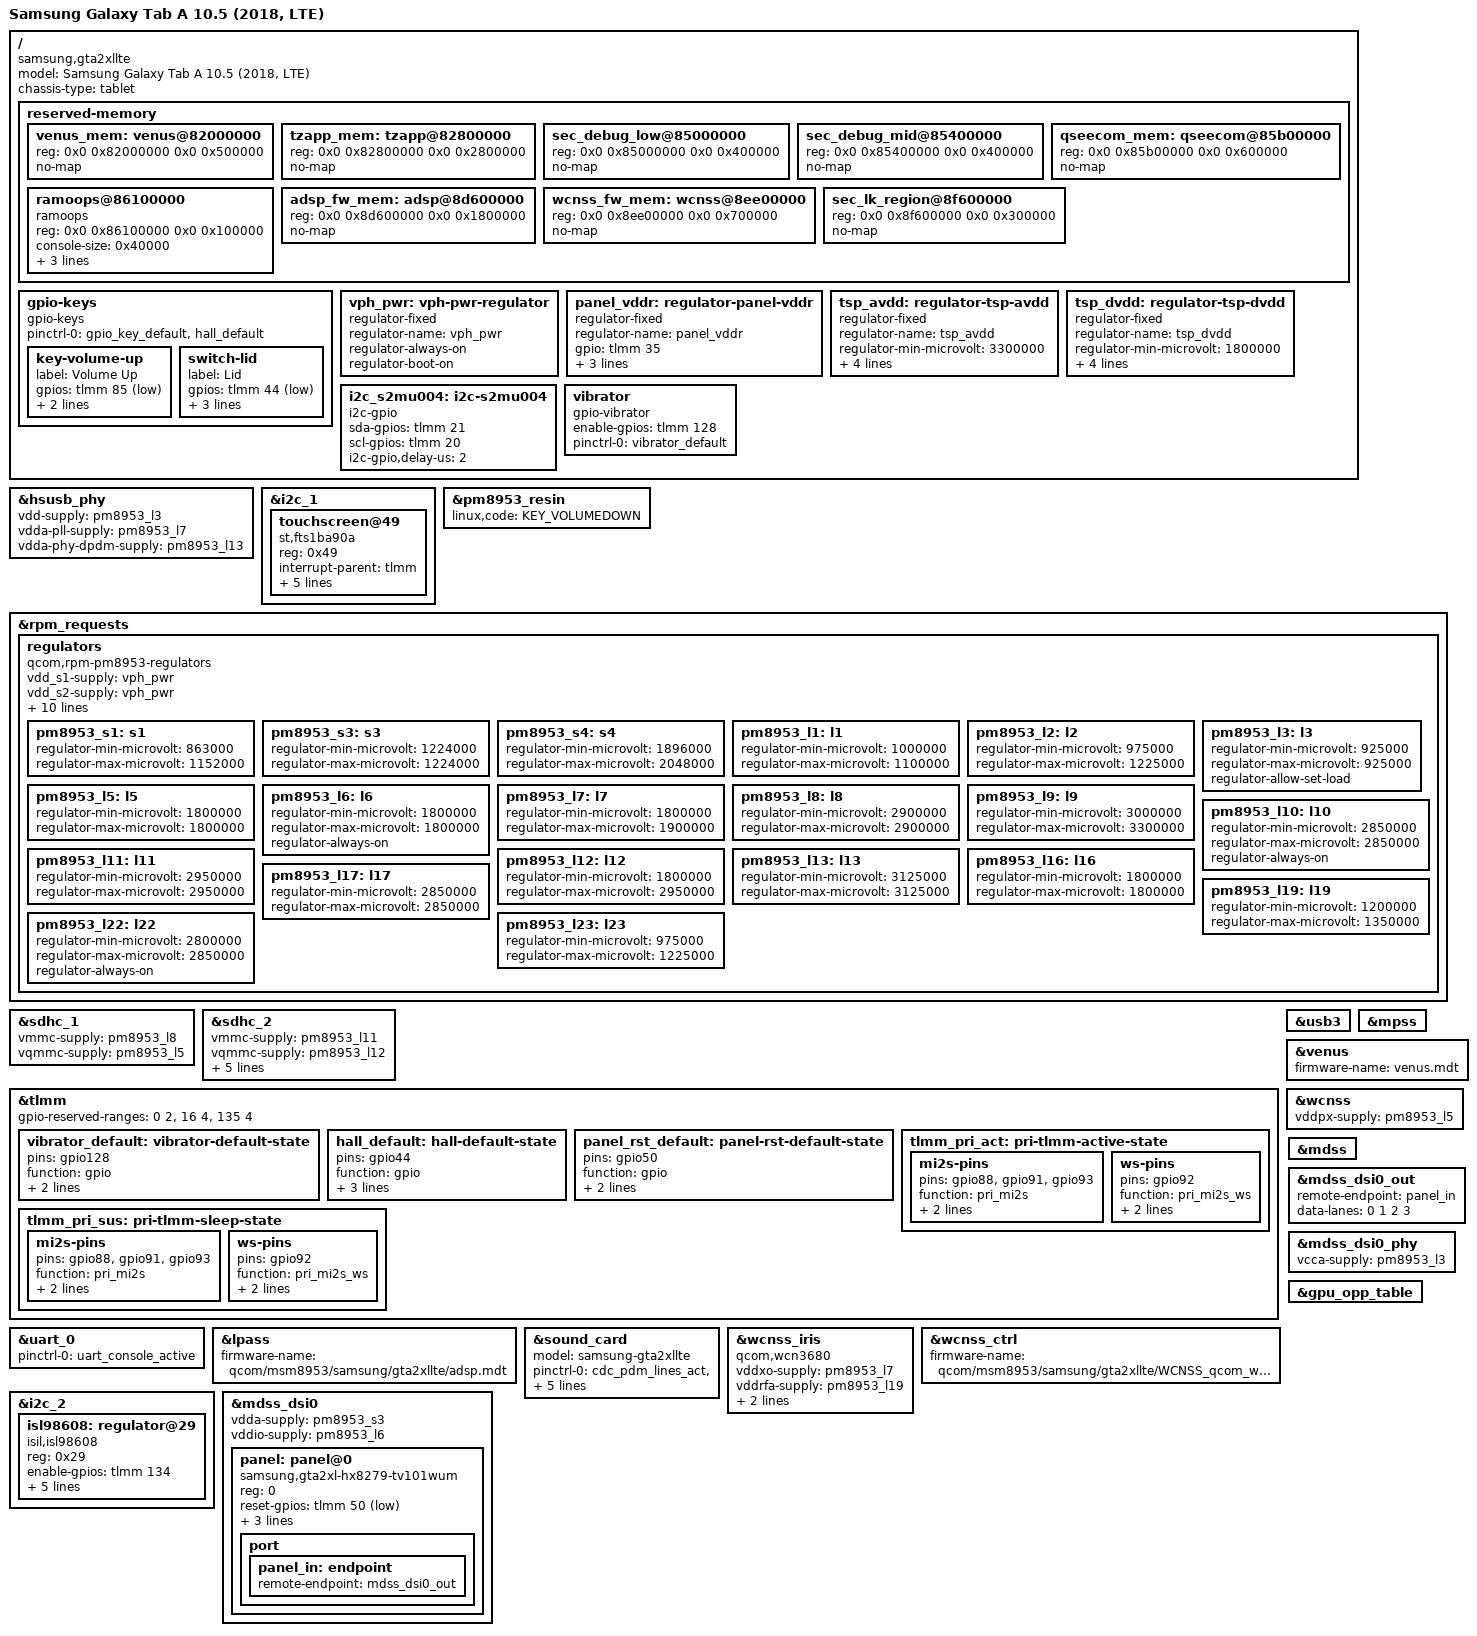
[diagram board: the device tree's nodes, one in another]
// SPDX-License-Identifier: GPL-2.0-only
/*
 * Samsung Galaxy Tab A 10.5 (2018, LTE) — "gta2xllte"
 * SoC: Qualcomm SDM450 / MSM8953 family
 *
 * testrung2 — riktig DSI-panel istället för simpledrm.
 *
 * SYFTE: msm-drivrutinen begär interconnect-bandbredd, det gör inte
 * simple-framebuffer. Därför dör bilden när venus probear klart och
 * interconnect kör sync_state(). Med &mdss aktiv ska både panelen och
 * venus fungera samtidigt.
 *
 * Ändringar mot testrung1:
 *   1. chosen/framebuffer BORTTAGEN — simpledrm och msm kan inte äga
 *      samma buffer.
 *   2. &mdss, &mdss_dsi0, &mdss_dsi0_phy = okay
 *   3. panel@0 med compatible "samsung,gta2xl-hx8279-tv101wum"
 *   4. &mdss_dsi0_out kopplad till panelen, 4 lanes
 *
 * KRÄVER att dessa drivrutiner är inbyggda i kärnan:
 *   panel-samsung-gta2xl-hx8279-tv101wum.c  (drivers/gpu/drm/panel/)
 *   isl98608-regulator.c                    (drivers/regulator/)
 * Saknas panel-drivern blir det INGEN bild alls. RAM-boota detta.
 *
 * OSÄKERT:
 *   - reset-gpio:ns aktiva nivå. Samsung anger den i panel-dtsi:n, inte i
 *     board-filen. GPIO_ACTIVE_LOW är det vanliga och vad drivern antar
 *     (devm_gpiod_get(..., GPIOD_OUT_HIGH) + set_value(1)->(0) i reset).
 *   - vdda/vddio/vcca-rails är tagna från msm8953-flipkart-rimob.dts, inte
 *     verifierade mot gta2xllte.
 *
 * Ingen backlight-property: panel-drivern registrerar egen DCS-backlight
 * (mipi_dsi_dcs_set_display_brightness_large), och Samsung anger
 * bl_ctrl_dcs. Det finns ingen pmi8950/wled på den här plattan.
 *
 * Inget behövs för zap: msm8953.dtsi har redan
 * firmware-name = "a506_zap.mdt" utan katalog, vilket matchar /lib/firmware-roten.
 * Inget behövs för tzapp: ingen nod refererar tzapp_mem, det är bara en
 * minnesreservering.
 */

/dts-v1/;

#include "sdm450.dtsi"
#include "pm8953.dtsi"

/delete-node/ &wcnss_fw_mem;

/delete-node/ &venus_mem;

/ {
	model = "Samsung Galaxy Tab A 10.5 (2018, LTE)";
	compatible = "samsung,gta2xllte", "qcom,sdm450";
	chassis-type = "tablet";

	reserved-memory {
		venus_mem: venus@82000000 {
			reg = <0x0 0x82000000 0x0 0x500000>;
			no-map;
		};

		tzapp_mem: tzapp@82800000 {
			reg = <0x0 0x82800000 0x0 0x2800000>;
			no-map;
		};

		sec_debug_low@85000000 {
			reg = <0x0 0x85000000 0x0 0x400000>;
			no-map;
		};

		sec_debug_mid@85400000 {
			reg = <0x0 0x85400000 0x0 0x400000>;
			no-map;
		};

		qseecom_mem: qseecom@85b00000 {
			reg = <0x0 0x85b00000 0x0 0x600000>;
			no-map;
		};

		ramoops@86100000 {
			compatible = "ramoops";
			reg = <0x0 0x86100000 0x0 0x100000>;

			console-size = <0x40000>;
			record-size = <0x3f800>;
			pmsg-size = <0x800>;
			ecc-size = <0>;
		};

		adsp_fw_mem: adsp@8d600000 {
			reg = <0x0 0x8d600000 0x0 0x1800000>;
			no-map;
		};

		wcnss_fw_mem: wcnss@8ee00000 {
			reg = <0x0 0x8ee00000 0x0 0x700000>;
			no-map;
		};

		sec_lk_region@8f600000 {
			reg = <0x0 0x8f600000 0x0 0x300000>;
			no-map;
		};
	};

	/*
	 * chosen/framebuffer (simpledrm) borttagen — msm-drivrutinen tar över
	 * displayen. Behöver du falla tillbaka: kopiera blocket från testrung1
	 * och sätt &mdss/&mdss_dsi0/&mdss_dsi0_phy till "disabled" igen.
	 *
	 * cont-splash-regionen ligger kvar reserverad (0x90001000, 20476 KiB)
	 * så lk2nd:s bild inte skrivs över innan msm är uppe.
	 */

	gpio-keys {
		compatible = "gpio-keys";

		pinctrl-names = "default";
		pinctrl-0 = <&gpio_key_default &hall_default>;

		key-volume-up {
			label = "Volume Up";
			gpios = <&tlmm 85 GPIO_ACTIVE_LOW>;
			linux,code = <KEY_VOLUMEUP>;
			wakeup-source;
		};

		/*
		 * Hall-sensor för magnetiskt fodral (book cover).
		 * Samsung: sdm450-sec-gta2xllte_eur_open-r05.dts rad 91,
		 *   hall { compatible = "hall";
		 *          hall,gpio_flip_cover = <&tlmm 44 0x1>; }
		 * 0x1 = aktiv låg. Rapporteras som SW_LID så logind/Plasma
		 * kan blanka skärmen när fodralet stängs.
		 */
		switch-lid {
			label = "Lid";
			gpios = <&tlmm 44 GPIO_ACTIVE_LOW>;
			linux,input-type = <EV_SW>;
			linux,code = <SW_LID>;
			wakeup-source;
		};

		/* Volume Down and Power are handled by the PMIC (see &pm8953_resin
		 * and the pm8953 pon below) */
	};

	vph_pwr: vph-pwr-regulator {
		compatible = "regulator-fixed";
		regulator-name = "vph_pwr";
		regulator-always-on;
		regulator-boot-on;
	};

	/*
	 * Panel VDDR (1.5V) extra rail — downstream samsung,panel-extra-power-gpio1
	 * on tlmm 35. The generated HX8279 driver doesn't request it, so assert it
	 * always-on so the panel has power before/through init.
	 */
	panel_vddr: regulator-panel-vddr {
		compatible = "regulator-fixed";
		regulator-name = "panel_vddr";
		gpio = <&tlmm 35 GPIO_ACTIVE_HIGH>;
		enable-active-high;
		regulator-always-on;
		regulator-boot-on;
	};

	/*
	 * Touchscreen power — downstream uses gpio-gated fixed regulators
	 * (NOT pm8953 rails): tsp_avdd 3.3V on tlmm 139, tsp_dvdd 1.8V on tlmm 140.
	 */
	tsp_avdd: regulator-tsp-avdd {
		compatible = "regulator-fixed";
		regulator-name = "tsp_avdd";
		regulator-min-microvolt = <3300000>;
		regulator-max-microvolt = <3300000>;
		gpio = <&tlmm 139 GPIO_ACTIVE_HIGH>;
		enable-active-high;
		regulator-boot-on;
	};

	tsp_dvdd: regulator-tsp-dvdd {
		compatible = "regulator-fixed";
		regulator-name = "tsp_dvdd";
		regulator-min-microvolt = <1800000>;
		regulator-max-microvolt = <1800000>;
		gpio = <&tlmm 140 GPIO_ACTIVE_HIGH>;
		enable-active-high;
		regulator-boot-on;
	};

	i2c_s2mu004: i2c-s2mu004 {
		compatible = "i2c-gpio";
		sda-gpios = <&tlmm 21 (GPIO_ACTIVE_HIGH | GPIO_OPEN_DRAIN)>;
		scl-gpios = <&tlmm 20 (GPIO_ACTIVE_HIGH | GPIO_OPEN_DRAIN)>;
		i2c-gpio,delay-us = <2>;	/* ~100 kHz */
		#address-cells = <1>;
		#size-cells = <0>;
	};
};

&hsusb_phy {
	vdd-supply = <&pm8953_l3>;
	vdda-pll-supply = <&pm8953_l7>;
	vdda-phy-dpdm-supply = <&pm8953_l13>;

	status = "okay";
};

&i2c_1 {
	status = "okay";

	touchscreen@49 {
		compatible = "st,fts1ba90a";
		reg = <0x49>;

		interrupt-parent = <&tlmm>;
		interrupts = <59 IRQ_TYPE_LEVEL_LOW>;

		vdd-supply = <&tsp_dvdd>;	/* 1.8V digital (tlmm 140) */
		avdd-supply = <&tsp_avdd>;	/* 3.3V analog (tlmm 139) */

		touchscreen-size-x = <1200>;
		touchscreen-size-y = <1920>;
	};
};

&pm8953_resin {
	linux,code = <KEY_VOLUMEDOWN>;
	status = "okay";
};

&rpm_requests {
	regulators {
		compatible = "qcom,rpm-pm8953-regulators";

		vdd_s1-supply = <&vph_pwr>;
		vdd_s2-supply = <&vph_pwr>;
		vdd_s3-supply = <&vph_pwr>;
		vdd_s4-supply = <&vph_pwr>;
		vdd_s5-supply = <&vph_pwr>;
		vdd_s6-supply = <&vph_pwr>;
		vdd_s7-supply = <&vph_pwr>;
		vdd_l1-supply = <&pm8953_s3>;
		vdd_l2_l3-supply = <&pm8953_s3>;
		vdd_l4_l5_l6_l7_l16_l19-supply = <&pm8953_s4>;
		vdd_l8_l11_l12_l13_l14_l15-supply = <&vph_pwr>;
		vdd_l9_l10_l17_l18_l22-supply = <&vph_pwr>;

		pm8953_s1: s1 {
			regulator-min-microvolt = <863000>;
			regulator-max-microvolt = <1152000>;
		};

		pm8953_s3: s3 {
			regulator-min-microvolt = <1224000>;
			regulator-max-microvolt = <1224000>;
		};

		pm8953_s4: s4 {
			regulator-min-microvolt = <1896000>;
			regulator-max-microvolt = <2048000>;
		};

		pm8953_l1: l1 {
			regulator-min-microvolt = <1000000>;
			regulator-max-microvolt = <1100000>;
		};

		pm8953_l2: l2 {
			regulator-min-microvolt = <975000>;
			regulator-max-microvolt = <1225000>;
		};

		pm8953_l3: l3 {
			regulator-min-microvolt = <925000>;
			regulator-max-microvolt = <925000>;
			regulator-allow-set-load;
		};

		pm8953_l5: l5 {
			regulator-min-microvolt = <1800000>;
			regulator-max-microvolt = <1800000>;
		};

		pm8953_l6: l6 {
			regulator-min-microvolt = <1800000>;
			regulator-max-microvolt = <1800000>;
			regulator-always-on;
		};

		pm8953_l7: l7 {
			regulator-min-microvolt = <1800000>;
			regulator-max-microvolt = <1900000>;
		};

		pm8953_l8: l8 {
			regulator-min-microvolt = <2900000>;
			regulator-max-microvolt = <2900000>;
		};

		pm8953_l9: l9 {
			regulator-min-microvolt = <3000000>;
			regulator-max-microvolt = <3300000>;
		};

		pm8953_l10: l10 {
			regulator-min-microvolt = <2850000>;
			regulator-max-microvolt = <2850000>;
			regulator-always-on;
		};

		pm8953_l11: l11 {
			regulator-min-microvolt = <2950000>;
			regulator-max-microvolt = <2950000>;
		};

		pm8953_l12: l12 {
			regulator-min-microvolt = <1800000>;
			regulator-max-microvolt = <2950000>;
		};

		pm8953_l13: l13 {
			regulator-min-microvolt = <3125000>;
			regulator-max-microvolt = <3125000>;
		};

		pm8953_l16: l16 {
			regulator-min-microvolt = <1800000>;
			regulator-max-microvolt = <1800000>;
		};

		pm8953_l17: l17 {
			regulator-min-microvolt = <2850000>;
			regulator-max-microvolt = <2850000>;
		};

		pm8953_l19: l19 {
			regulator-min-microvolt = <1200000>;
			regulator-max-microvolt = <1350000>;
		};

		pm8953_l22: l22 {
			regulator-min-microvolt = <2800000>;
			regulator-max-microvolt = <2850000>;
			regulator-always-on;
		};

		pm8953_l23: l23 {
			regulator-min-microvolt = <975000>;
			regulator-max-microvolt = <1225000>;
		};
	};
};

&sdhc_1 {
	vmmc-supply = <&pm8953_l8>;
	vqmmc-supply = <&pm8953_l5>;

	status = "okay";
};

&sdhc_2 {
	vmmc-supply = <&pm8953_l11>;
	vqmmc-supply = <&pm8953_l12>;

	cd-gpios = <&tlmm 133 GPIO_ACTIVE_LOW>;

	pinctrl-names = "default", "sleep";
	pinctrl-0 = <&sdc2_clk_on &sdc2_cmd_on &sdc2_data_on &sdc2_cd_on>;
	pinctrl-1 = <&sdc2_clk_off &sdc2_cmd_off &sdc2_data_off &sdc2_cd_off>;

	status = "okay";
};

&tlmm {
	gpio-reserved-ranges = <0 2>, <16 4>, <135 4>;
};

&uart_0 {
	pinctrl-names = "default";
	pinctrl-0 = <&uart_console_active>;

	status = "okay";
};

&usb3 {
	status = "okay";
};

&mpss {
	status = "okay";
};

&lpass {
	firmware-name = "qcom/msm8953/samsung/gta2xllte/adsp.mdt";
	status = "okay";
};

/*
 * Venus. Drivern probear redan och modulkedjan är laddad — det enda som
 * felade var firmwaren:
 *   "Direct firmware load for venus.mdt failed with error -2"
 * Ligger venus.mdt i /lib/firmware-roten behövs ingen firmware-name alls;
 * den här raden gör sökvägen explicit. Peka om den om du flyttar filen.
 */
&venus {
	firmware-name = "venus.mdt";
	status = "okay";
};

  &sound_card {
        model = "samsung-gta2xllte";

        pinctrl-names = "default", "sleep";
        pinctrl-0 = <&cdc_pdm_lines_act
                &cdc_pdm_lines_2_act
                &cdc_pdm_comp_lines_act
                &tlmm_pri_act>;
        pinctrl-1 = <&cdc_pdm_lines_sus
                &cdc_pdm_lines_2_sus
                &cdc_pdm_comp_lines_sus
                &tlmm_pri_sus>;

        status = "okay";
  };

&wcnss {
	vddpx-supply = <&pm8953_l5>;
	
	status = "okay";
};

&wcnss_iris {
	compatible = "qcom,wcn3680";

	vddxo-supply = <&pm8953_l7>;
	vddrfa-supply = <&pm8953_l19>;
	vddpa-supply = <&pm8953_l9>;
	vdddig-supply = <&pm8953_l5>;
};

&wcnss_ctrl {
	firmware-name = "qcom/msm8953/samsung/gta2xllte/WCNSS_qcom_wlan_nv.bin";
};

&i2c_2 {
	status = "okay";

	isl98608: regulator@29 {
		compatible = "isil,isl98608";
		reg = <0x29>;
		enable-gpios = <&tlmm 134 GPIO_ACTIVE_HIGH>;
		regulator-name = "panel_vsp_vsn";
		regulator-min-microvolt = <5800000>;
		regulator-max-microvolt = <5800000>;
		regulator-always-on;
		regulator-boot-on;
	};
};

&mdss {
	status = "okay";
};

&mdss_dsi0 {
	vdda-supply = <&pm8953_s3>;	/* 1.224 V — ej verifierad mot gta2 */
	vddio-supply = <&pm8953_l6>;	/* 1.8 V, always-on */

	status = "okay";

	panel: panel@0 {
		compatible = "samsung,gta2xl-hx8279-tv101wum";
		reg = <0>;

		/*
		 * LCD_RST. Samsung display-r00.dtsi listar gpio50 + gpio35 som
		 * "LCD_RST & LCD_LDO_EN". gpio35 är panel_vddr (always-on).
		 */
		reset-gpios = <&tlmm 50 GPIO_ACTIVE_LOW>;

		pinctrl-names = "default";
		pinctrl-0 = <&panel_rst_default>;

		/*
		 * Båda pekar på samma nod med flit: isl98608 är modellerad som
		 * en enable-only regulator som drar upp både VSP och VSN (~5.8 V).
		 * Står i huvudkommentaren till isl98608-regulator.c.
		 */
		vsp-supply = <&isl98608>;
		vsn-supply = <&isl98608>;

		port {
			panel_in: endpoint {
				remote-endpoint = <&mdss_dsi0_out>;
			};
		};
	};
};

&mdss_dsi0_out {
	remote-endpoint = <&panel_in>;
	data-lanes = <0 1 2 3>;
};

&mdss_dsi0_phy {
	vcca-supply = <&pm8953_l3>;	/* 0.925 V — ej verifierad mot gta2 */

	status = "okay";
};


/ {
	vibrator {
		compatible = "gpio-vibrator";
		enable-gpios = <&tlmm 128 GPIO_ACTIVE_HIGH>;

		pinctrl-names = "default";
		pinctrl-0 = <&vibrator_default>;
	};
};

&tlmm {
	vibrator_default: vibrator-default-state {
		pins = "gpio128";
		function = "gpio";
		drive-strength = <2>;
		bias-disable;
	};

	/*
	 * Hall-sensor, gpio44. Värden från Samsungs hall_pinctrl
	 * (sdm450-sec-gta2xllte_eur_open-pinctrl-r05.dtsi rad 87).
	 */
	hall_default: hall-default-state {
		pins = "gpio44";
		function = "gpio";
		drive-strength = <2>;
		bias-pull-up;
		input-enable;
	};

	/*
	 * LCD_RST (gpio50). Samsung: display-r00.dtsi, "LCD_RST & LCD_LDO_EN"
	 * på gpio50/gpio35. gpio35 har vi redan som panel_vddr.
	 * Oanvänd så länge &mdss är disabled — ligger här för att vara redo.
	 * Aktiv nivå för reset är INTE verifierad.
	 */
	panel_rst_default: panel-rst-default-state {
		pins = "gpio50";
		function = "gpio";
		drive-strength = <8>;
		bias-disable;
	};
	tlmm_pri_act: pri-tlmm-active-state {
                mi2s-pins {
                        pins = "gpio88", "gpio91", "gpio93";
                        function = "pri_mi2s";
                        drive-strength = <8>;
                        bias-disable;
                };

                ws-pins {
                        pins = "gpio92";
                        function = "pri_mi2s_ws";
                        drive-strength = <8>;
                        bias-disable;
                };
        };

        tlmm_pri_sus: pri-tlmm-sleep-state {
                mi2s-pins {
                        pins = "gpio88", "gpio91", "gpio93";
                        function = "pri_mi2s";
                        drive-strength = <2>;
                        bias-disable;
                };

                ws-pins {
                        pins = "gpio92";
                        function = "pri_mi2s_ws";
                        drive-strength = <2>;
                        bias-disable;
                };
        };
};

&gpu_opp_table {
	/delete-node/ opp-600000000;
	/delete-node/ opp-560000000;
};
